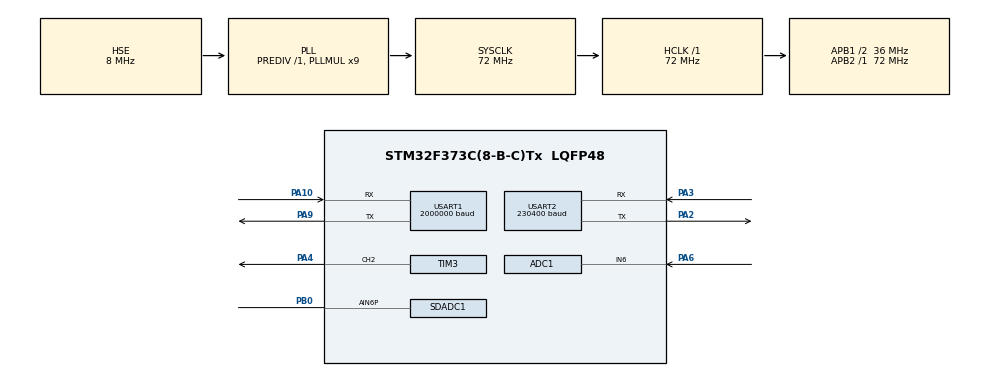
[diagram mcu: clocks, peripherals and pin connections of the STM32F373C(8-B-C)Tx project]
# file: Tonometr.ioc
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ADC1.Channel-8\#ChannelRegularConversion=ADC_CHANNEL_6
ADC1.ContinuousConvMode=ENABLE
ADC1.EnableRegularConversion=ENABLE
ADC1.ExternalTrigConv=ADC_SOFTWARE_START
ADC1.NbrOfConversionFlag=1
ADC1.Rank-8\#ChannelRegularConversion=1
ADC1.SamplingTime-8\#ChannelRegularConversion=ADC_SAMPLETIME_239CYCLES_5
ADC1.master=1
Dma.ADC1.1.Direction=DMA_PERIPH_TO_MEMORY
Dma.ADC1.1.Instance=DMA1_Channel1
Dma.ADC1.1.MemDataAlignment=DMA_MDATAALIGN_HALFWORD
Dma.ADC1.1.MemInc=DMA_MINC_ENABLE
Dma.ADC1.1.Mode=DMA_NORMAL
Dma.ADC1.1.PeriphDataAlignment=DMA_PDATAALIGN_HALFWORD
Dma.ADC1.1.PeriphInc=DMA_PINC_DISABLE
Dma.ADC1.1.Priority=DMA_PRIORITY_LOW
Dma.Request0=USART2_TX
Dma.Request1=ADC1
Dma.USART2_TX.0.Direction=DMA_MEMORY_TO_PERIPH
Dma.USART2_TX.0.Instance=DMA1_Channel7
Dma.USART2_TX.0.MemDataAlignment=DMA_MDATAALIGN_BYTE
Dma.USART2_TX.0.MemInc=DMA_MINC_ENABLE
Dma.USART2_TX.0.Mode=DMA_NORMAL
Dma.USART2_TX.0.PeriphDataAlignment=DMA_PDATAALIGN_BYTE
Dma.USART2_TX.0.PeriphInc=DMA_PINC_DISABLE
Dma.USART2_TX.0.Priority=DMA_PRIORITY_LOW
Mcu.Family=STM32F3
Mcu.Name=STM32F373C(8-B-C)Tx
Mcu.Package=LQFP48
NVIC.DMA1_Channel1_IRQn=true\:0\:0\:false\:false\:true\:false\:true\:true
NVIC.DMA1_Channel7_IRQn=true\:0\:0\:false\:false\:true\:false\:true\:true
NVIC.PriorityGroup=NVIC_PRIORITYGROUP_4
NVIC.SDADC1_IRQn=true\:0\:0\:false\:false\:true\:true\:true\:true
NVIC.TIM18_DAC2_IRQn=true\:15\:0\:false\:false\:true\:false\:true\:true
NVIC.TimeBase=TIM18_DAC2_IRQn
NVIC.TimeBaseIP=TIM18
NVIC.USART2_IRQn=true\:0\:0\:false\:false\:true\:true\:true\:true
PA10.GPIO_PuPd=GPIO_PULLUP
PA10.Mode=Asynchronous
PA10.Signal=USART1_RX
PA13.Mode=Serial_Wire
PA13.Signal=SYS_JTMS-SWDIO
PA14.Mode=Serial_Wire
PA14.Signal=SYS_JTCK-SWCLK
PA2.GPIO_PuPd=GPIO_PULLUP
PA2.Mode=Asynchronous
PA2.Signal=USART2_TX
PA3.GPIO_PuPd=GPIO_PULLUP
PA3.Mode=Asynchronous
PA3.Signal=USART2_RX
PA4.Signal=S_TIM3_CH2
PA6.Mode=IN6
PA6.Signal=ADC1_IN6
PA9.GPIO_PuPd=GPIO_PULLUP
PA9.Mode=Asynchronous
PA9.Signal=USART1_TX
PB0.Mode=IN6-Single-Ended
PB0.Signal=SDADC1_AIN6P
PF0-OSC_IN.Mode=HSE-External-Oscillator
PF0-OSC_IN.Signal=RCC_OSC_IN
PF1-OSC_OUT.Mode=HSE-External-Oscillator
PF1-OSC_OUT.Signal=RCC_OSC_OUT
ProjectManager.HeapSize=0x400
ProjectManager.StackSize=0x800
ProjectManager.TargetToolchain=STM32CubeIDE
RCC.AHBFreq_Value=72000000
RCC.APB1CLKDivider=RCC_HCLK_DIV2
RCC.APB1Freq_Value=36000000
RCC.APB1TimFreq_Value=72000000
RCC.APB2Freq_Value=72000000
RCC.APB2TimFreq_Value=72000000
RCC.CortexFreq_Value=72000000
RCC.HCLKFreq_Value=72000000
RCC.HSE_VALUE=8000000
RCC.HSI_VALUE=8000000
RCC.LSE_VALUE=32768
RCC.PLLMUL=RCC_PLL_MUL9
RCC.PLLSourceVirtual=RCC_PLLSOURCE_HSE
RCC.SDADCPresc=RCC_SDADCSYSCLK_DIV48
RCC.SYSCLKFreq_VALUE=72000000
RCC.SYSCLKSource=RCC_SYSCLKSOURCE_PLLCLK
RCC.USBFreq_Value=72000000
SDADC1.Channel-0\#ChannelRegularConversion=SDADC_CHANNEL_6
SDADC1.CommonMode0=SDADC_COMMON_MODE_VSSA
SDADC1.ConfIndex-0\#ChannelRegularConversion=SDADC_CONF_INDEX_0
SDADC1.ContinuousMode=SDADC_CONTINUOUS_CONV_ON
SDADC1.EnableInjectedConversion=DISABLE
SDADC1.EnableRegularconversion=ENABLE
SDADC1.Gain0=SDADC_GAIN_1_2
SDADC1.InputMode0=SDADC_INPUT_MODE_SE_OFFSET
SDADC1.NbrOfConversionFlag=1
SDADC1.Offset0=0
SDADC1.ReferenceVoltage=SDADC_VREF_VDDA
SH.S_TIM3_CH2.0=TIM3_CH2,PWM Generation2 CH2
TIM19.AutoReloadPreload=TIM_AUTORELOAD_PRELOAD_ENABLE
TIM19.Period=49999
TIM19.Prescaler=2
TIM19.TIM_MasterOutputTrigger=TIM_TRGO_UPDATE
TIM3.Channel-PWM\ Generation2\ CH2=TIM_CHANNEL_2
TIM3.OCPolarity_2=TIM_OCPOLARITY_LOW
TIM3.Period=30000
TIM3.Prescaler=0
TIM3.Pulse-PWM\ Generation2\ CH2=15000
USART1.BaudRate=2000000
USART1.VirtualMode-Asynchronous=VM_ASYNC
USART2.BaudRate=230400
USART2.VirtualMode-Asynchronous=VM_ASYNC
VP_SDADC1_CONF0.Mode=ConfigZero
VP_SYS_VS_tim18.Mode=TIM18
VP_TIM19_VS_ClockSourceINT.Mode=Internal
board=custom

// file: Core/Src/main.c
/* USER CODE BEGIN Header */
/**
  ******************************************************************************
  * @file           : main.c
  * @brief          : Main program body
  ******************************************************************************
  * @attention
  *
  * Copyright (c) 2023 STMicroelectronics.
  * All rights reserved.
  *
  * This software is licensed under terms that can be found in the LICENSE file
  * in the root directory of this software component.
  * If no LICENSE file comes with this software, it is provided AS-IS.
  *
  ******************************************************************************
  */
/* USER CODE END Header */
#include "main.h"
#include "adc.h"
#include "dma.h"
#include "sdadc.h"
#include "tim.h"
#include "usart.h"
#include "gpio.h"

/* USER CODE BEGIN Includes */
 extern void setup();
/* USER CODE END Includes */

void SystemClock_Config(void);

int main(void)
{

  /* MCU Configuration--------------------------------------------------------*/

  /* Reset of all peripherals, Initializes the Flash interface and the Systick. */
  HAL_Init();

  /* Configure the system clock */
  SystemClock_Config();

  /* Initialize all configured peripherals */
  MX_GPIO_Init();
  MX_DMA_Init();
  MX_SDADC1_Init();
  MX_USART1_UART_Init();
  MX_USART2_UART_Init();
  MX_ADC1_Init();
  MX_TIM19_Init();
  MX_TIM3_Init();
  /* USER CODE BEGIN 2 */
   setup();
  /* USER CODE END 2 */

  /* Infinite loop */
  while (1)
  {

  }
}

void SystemClock_Config(void)
{
  RCC_OscInitTypeDef RCC_OscInitStruct = {0};
  RCC_ClkInitTypeDef RCC_ClkInitStruct = {0};
  RCC_PeriphCLKInitTypeDef PeriphClkInit = {0};

  /** Initializes the RCC Oscillators according to the specified parameters
  * in the RCC_OscInitTypeDef structure.
  */
  RCC_OscInitStruct.OscillatorType = RCC_OSCILLATORTYPE_HSE;
  RCC_OscInitStruct.HSEState = RCC_HSE_ON;
  RCC_OscInitStruct.HSEPredivValue = RCC_HSE_PREDIV_DIV1;
  RCC_OscInitStruct.HSIState = RCC_HSI_ON;
  RCC_OscInitStruct.PLL.PLLState = RCC_PLL_ON;
  RCC_OscInitStruct.PLL.PLLSource = RCC_PLLSOURCE_HSE;
  RCC_OscInitStruct.PLL.PLLMUL = RCC_PLL_MUL9;
  if (HAL_RCC_OscConfig(&RCC_OscInitStruct) != HAL_OK)
  {
    Error_Handler();
  }

  /** Initializes the CPU, AHB and APB buses clocks
  */
  RCC_ClkInitStruct.ClockType = RCC_CLOCKTYPE_HCLK|RCC_CLOCKTYPE_SYSCLK
                              |RCC_CLOCKTYPE_PCLK1|RCC_CLOCKTYPE_PCLK2;
  RCC_ClkInitStruct.SYSCLKSource = RCC_SYSCLKSOURCE_PLLCLK;
  RCC_ClkInitStruct.AHBCLKDivider = RCC_SYSCLK_DIV1;
  RCC_ClkInitStruct.APB1CLKDivider = RCC_HCLK_DIV2;
  RCC_ClkInitStruct.APB2CLKDivider = RCC_HCLK_DIV1;

  if (HAL_RCC_ClockConfig(&RCC_ClkInitStruct, FLASH_LATENCY_2) != HAL_OK)
  {
    Error_Handler();
  }
  PeriphClkInit.PeriphClockSelection = RCC_PERIPHCLK_USART1|RCC_PERIPHCLK_USART2
                              |RCC_PERIPHCLK_ADC1|RCC_PERIPHCLK_SDADC;
  PeriphClkInit.Usart1ClockSelection = RCC_USART1CLKSOURCE_PCLK2;
  PeriphClkInit.Usart2ClockSelection = RCC_USART2CLKSOURCE_PCLK1;
  PeriphClkInit.SdadcClockSelection = RCC_SDADCSYSCLK_DIV48;
  PeriphClkInit.Adc1ClockSelection = RCC_ADC1PCLK2_DIV2;

  if (HAL_RCCEx_PeriphCLKConfig(&PeriphClkInit) != HAL_OK)
  {
    Error_Handler();
  }
  HAL_PWREx_EnableSDADC(PWR_SDADC_ANALOG1);
}

void HAL_TIM_PeriodElapsedCallback(TIM_HandleTypeDef *htim)
{
  if (htim->Instance == TIM18) {
    HAL_IncTick();
  }
}

void Error_Handler(void)
{
  __disable_irq();
  while (1)
  {
  }
}
